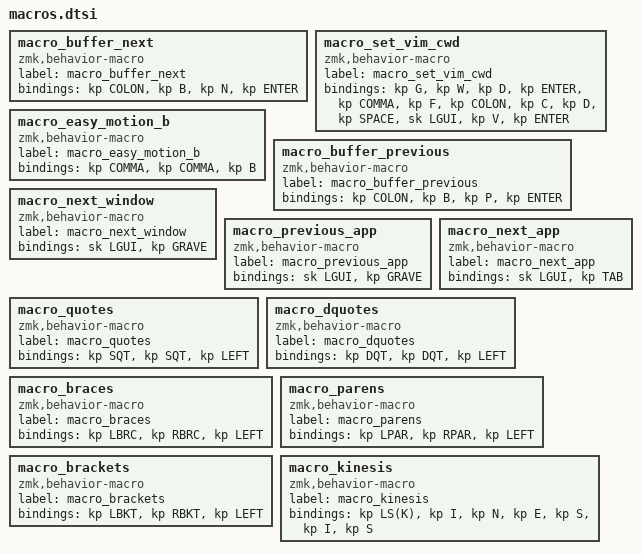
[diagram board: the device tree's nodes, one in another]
macro_buffer_next: macro_buffer_next{
compatible = "zmk,behavior-macro";
label = "macro_buffer_next";
#binding-cells = <0>;
bindings = <&kp COLON>, <&kp B>, <&kp N>, <&kp ENTER>;
};
macro_set_vim_cwd: macro_set_vim_cwd{
compatible = "zmk,behavior-macro";
label = "macro_set_vim_cwd";
#binding-cells = <0>;
bindings = <&kp G>, <&kp W>, <&kp D>, <&kp ENTER>, <&kp COMMA>, <&kp F>, <&kp COLON>, <&kp C>, <&kp D>, <&kp SPACE>, <&sk LGUI>, <&kp V>, <&kp ENTER>;
};
macro_easy_motion_b: macro_easy_motion_b{
compatible = "zmk,behavior-macro";
label = "macro_easy_motion_b";
#binding-cells = <0>;
bindings = <&kp COMMA>, <&kp COMMA>, <&kp B>;
};
macro_buffer_previous: macro_buffer_previous{
compatible = "zmk,behavior-macro";
label = "macro_buffer_previous";
#binding-cells = <0>;
bindings = <&kp COLON>, <&kp B>, <&kp P>, <&kp ENTER>;
};
macro_next_window: macro_next_window{
compatible = "zmk,behavior-macro";
label = "macro_next_window";
#binding-cells = <0>;
bindings = <&sk LGUI>, <&kp GRAVE>;
};
macro_previous_app: macro_previous_app{
compatible = "zmk,behavior-macro";
label = "macro_previous_app";
#binding-cells = <0>;
bindings = <&sk LGUI>, <&kp GRAVE>;
};
macro_next_app: macro_next_app{
compatible = "zmk,behavior-macro";
label = "macro_next_app";
#binding-cells = <0>;
bindings = <&sk LGUI>, <&kp TAB>;
};
macro_quotes: macro_quotes{
compatible = "zmk,behavior-macro";
label = "macro_quotes";
#binding-cells = <0>;
bindings = <&kp SQT>, <&kp SQT>, <&kp LEFT>;
};
macro_dquotes: macro_dquotes{
compatible = "zmk,behavior-macro";
label = "macro_dquotes";
#binding-cells = <0>;
bindings = <&kp DQT>, <&kp DQT>, <&kp LEFT>;
};
macro_braces: macro_braces{
compatible = "zmk,behavior-macro";
label = "macro_braces";
#binding-cells = <0>;
bindings = <&kp LBRC>, <&kp RBRC>, <&kp LEFT>;
};
macro_parens: macro_parens{
compatible = "zmk,behavior-macro";
label = "macro_parens";
#binding-cells = <0>;
bindings = <&kp LPAR>, <&kp RPAR>, <&kp LEFT>;
};
macro_brackets: macro_brackets{
compatible = "zmk,behavior-macro";
label = "macro_brackets";
#binding-cells = <0>;
bindings = <&kp LBKT>, <&kp RBKT>, <&kp LEFT>;
};
macro_kinesis: macro_kinesis{
compatible = "zmk,behavior-macro";
label = "macro_kinesis";
#binding-cells = <0>;
bindings = <&kp LS(K)>, <&kp I>, <&kp N>, <&kp E>, <&kp S>, <&kp I>, <&kp S>;
};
